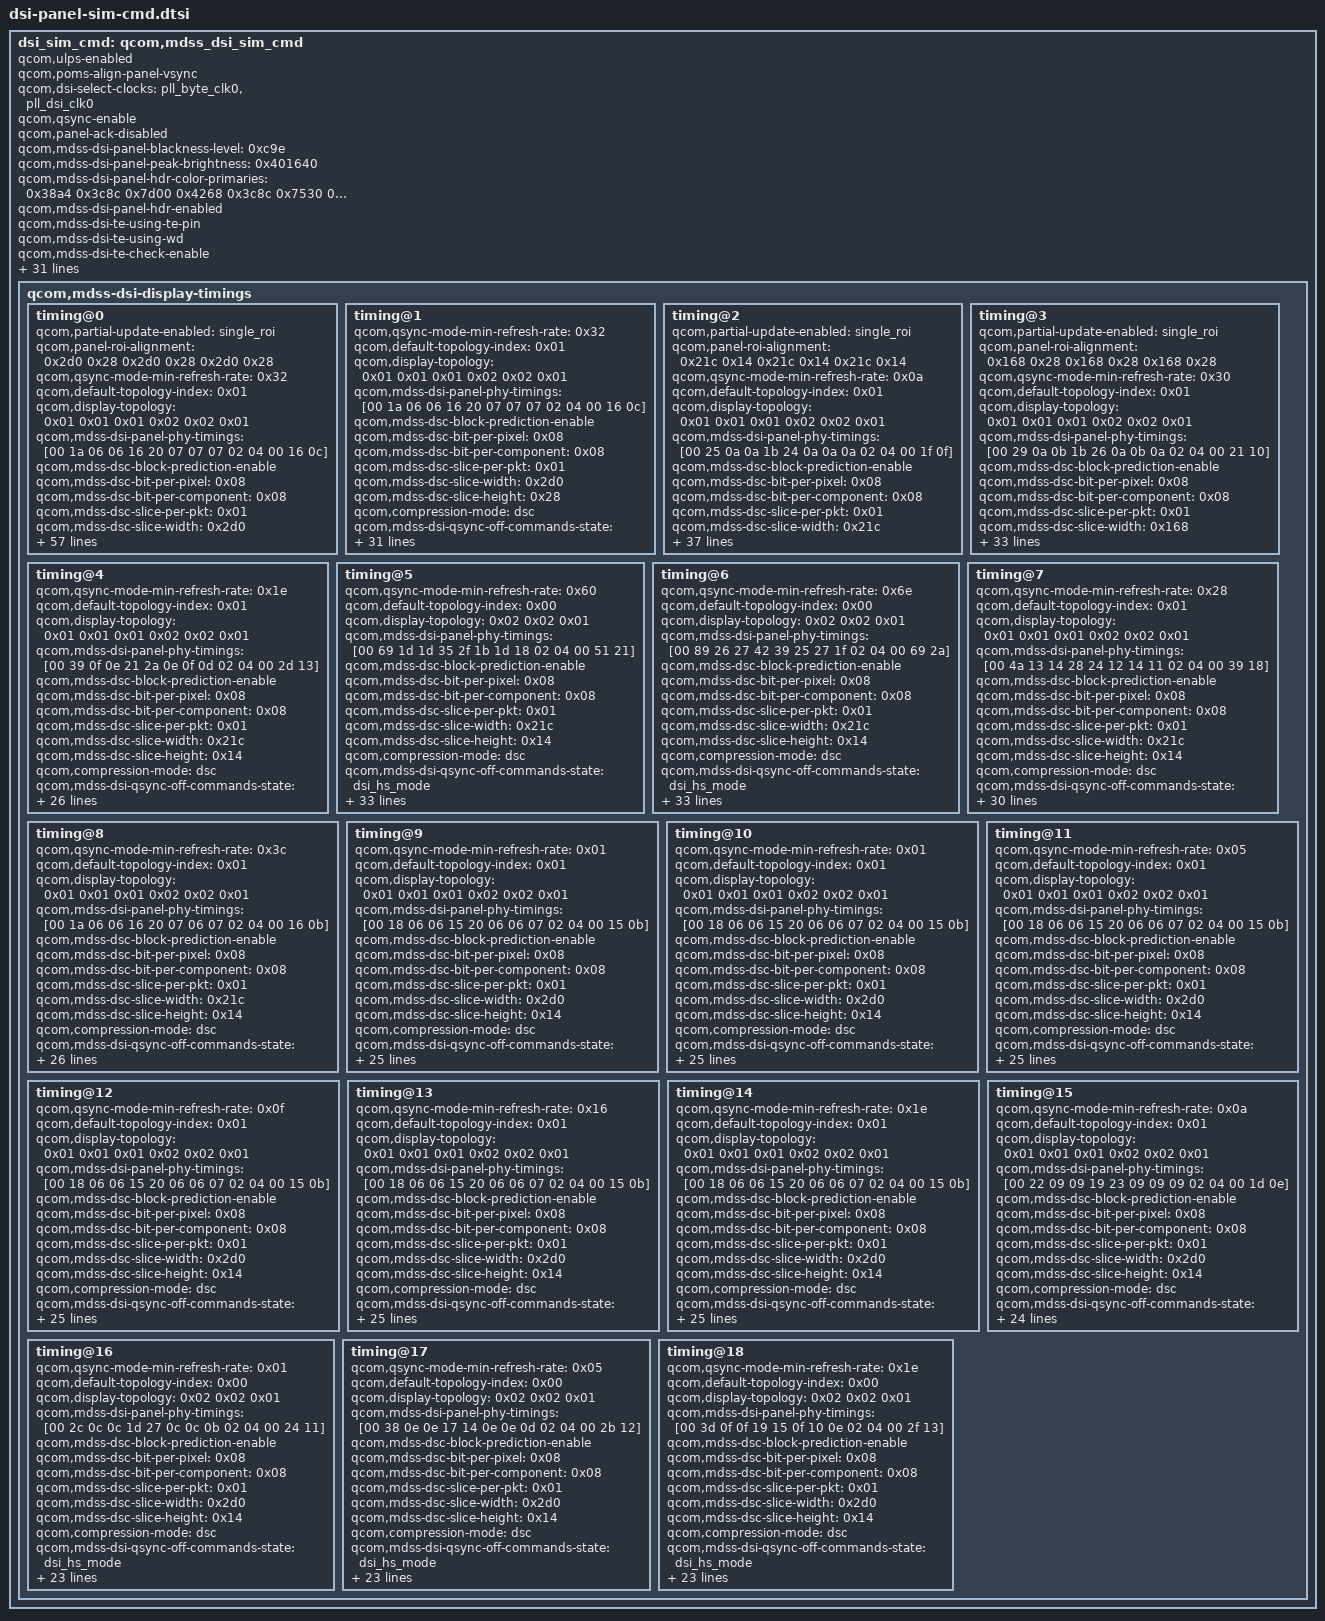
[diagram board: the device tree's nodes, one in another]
// SPDX-License-Identifier: BSD-3-Clause
/*
 * Copyright (c) 2023-2024 Qualcomm Innovation Center, Inc. All rights reserved.
 * Copyright (c) 2025 The LineageOS Project
 */

dsi_sim_cmd: qcom,mdss_dsi_sim_cmd {
	qcom,ulps-enabled;
	qcom,poms-align-panel-vsync;
	qcom,dsi-select-clocks = "pll_byte_clk0", "pll_dsi_clk0";
	qcom,qsync-enable;
	qcom,panel-ack-disabled;
	qcom,mdss-dsi-panel-blackness-level = <0xc9e>;
	qcom,mdss-dsi-panel-peak-brightness = <0x401640>;
	qcom,mdss-dsi-panel-hdr-color-primaries = <0x38a4 0x3c8c 0x7d00 0x4268 0x3c8c 0x7530 0x1f40 0xbb8>;
	qcom,mdss-dsi-panel-hdr-enabled;
	qcom,mdss-dsi-te-using-te-pin;
	qcom,mdss-dsi-te-using-wd;
	qcom,mdss-dsi-te-check-enable;
	qcom,mdss-dsi-te-dcs-command = <0x01>;
	qcom,mdss-dsi-wr-mem-continue = <0x3c>;
	qcom,mdss-dsi-wr-mem-start = <0x2c>;
	qcom,mdss-dsi-te-pin-select = <0x01>;
	qcom,mdss-dsi-mdp-trigger = "none";
	qcom,mdss-dsi-dma-trigger = "trigger_sw";
	qcom,mdss-dsi-bl-max-level = <0xfff>;
	qcom,mdss-dsi-t-clk-pre = <0x27>;
	qcom,mdss-dsi-t-clk-post = <0x03>;
	qcom,mdss-dsi-reset-sequence = <0x01 0x0a 0x00 0x0a 0x01 0x0a>;
	qcom,mdss-dsi-lane-3-state;
	qcom,mdss-dsi-lane-2-state;
	qcom,mdss-dsi-lane-1-state;
	qcom,mdss-dsi-lane-0-state;
	qcom,mdss-dsi-bllp-power-mode;
	qcom,mdss-dsi-bllp-eof-power-mode;
	qcom,mdss-dsi-traffic-mode = "non_burst_sync_event";
	qcom,mdss-dsi-panel-mode-switch;
	qcom,mdss-dsi-border-color = <0x00>;
	qcom,mdss-dsi-underflow-color = <0xff>;
	qcom,mdss-dsi-color-order = "rgb_swap_rgb";
	qcom,mdss-dsi-bpp = <0x18>;
	qcom,mdss-dsi-stream = <0x00>;
	qcom,mdss-dsi-virtual-channel-id = <0x00>;
	qcom,dsi-phy-num = <0x00>;
	qcom,dsi-ctrl-num = <0x00>;
	qcom,mdss-dsi-panel-type = "dsi_cmd_mode";
	qcom,mdss-dsi-panel-name = "Simulator cmd mode dsi panel";

	qcom,mdss-dsi-display-timings {

		timing@0 {
			qcom,partial-update-enabled = "single_roi";
			qcom,panel-roi-alignment = <0x2d0 0x28 0x2d0 0x28 0x2d0 0x28>;
			qcom,qsync-mode-min-refresh-rate = <0x32>;
			qcom,default-topology-index = <0x01>;
			qcom,display-topology = <0x01 0x01 0x01 0x02 0x02 0x01>;
			qcom,mdss-dsi-panel-phy-timings = [00 1a 06 06 16 20 07 07 07 02 04 00 16 0c];
			qcom,mdss-dsc-block-prediction-enable;
			qcom,mdss-dsc-bit-per-pixel = <0x08>;
			qcom,mdss-dsc-bit-per-component = <0x08>;
			qcom,mdss-dsc-slice-per-pkt = <0x01>;
			qcom,mdss-dsc-slice-width = <0x2d0>;
			qcom,mdss-dsc-slice-height = <0x28>;
			qcom,compression-mode = "dsc";
			qcom,mdss-dsi-qsync-off-commands-state = "dsi_hs_mode";
			qcom,mdss-dsi-qsync-off-commands = [15 01 00 00 00 00 02 51 00];
			qcom,mdss-dsi-qsync-on-commands-state = "dsi_hs_mode";
			qcom,mdss-dsi-qsync-on-commands = [15 01 00 00 00 00 02 51 00];
			qcom,cmd-mode-switch-out-commands-state = "dsi_lp_mode";
			qcom,cmd-mode-switch-out-commands = <0x39010000 0x3b0 0xa5000701 0x00 0x2010039 0x1000000 0x6b200 0x5d010249>;
			qcom,cmd-mode-switch-in-commands-state = "dsi_lp_mode";
			qcom,cmd-mode-switch-in-commands = [39 01 00 00 00 00 03 b0 a5 00 07 01 00 00 00 00 02 01 00 39 01 00 00 00 00 06 b2 00 5d 04 80 49 15 01 00 00 00 00 02 3d 11 15 01 00 00 00 00 02 36 00 15 01 00 00 00 00 02 55 0b];
			qcom,video-mode-switch-in-commands-state = "dsi_lp_mode";
			qcom,video-mode-switch-in-commands = [39 01 00 00 00 00 03 b0 a5 00 07 01 00 00 00 00 02 01 00 39 01 00 00 00 00 06 b2 00 5d 04 80 49 15 01 00 00 00 00 02 3d 10 15 01 00 00 00 00 02 36 00 15 01 00 00 00 00 02 55 0c];
			qcom,video-mode-switch-out-commands-state = "dsi_lp_mode";
			qcom,video-mode-switch-out-commands = <0x39010000 0x3b0 0xa5000701 0x00 0x2010039 0x1000000 0x6b200 0x5d048049>;
			qcom,mdss-dsi-off-command-state = "dsi_hs_mode";
			qcom,mdss-dsi-off-command = [05 01 00 00 32 00 02 28 00 05 01 00 00 78 00 02 10 00];
			qcom,mdss-dsi-on-command-state = "dsi_lp_mode";
			qcom,vid-on-commands = <0x29010000 0x2b0 0x3050100 0xa0001 0x150100 0xa0002 0x3a773901 0xa00 0x52a0000 0x4ff3901 0xa00 0x52b0000 0x59f1501 0xa00 0x2350039 0x100000a 0x34400 0x150100 0xa0002 0x51ff1501 0xa00 0x2532415 0x100000a 0x25500 0x5010000 0xf0000100>;
			qcom,cmd-on-commands = <0x29010000 0x2b0 0x3050100 0xa0001 0x150100 0xa0002 0x3a773901 0xa00 0x52a0000 0x4ff3901 0xa00 0x52b0000 0x59f1501 0xa00 0x2350039 0x100000a 0x34400 0x150100 0xa0002 0x51ff1501 0xa00 0x2532415 0x100000a 0x25500 0x5010000 0x78000111 0x5010000 0x10000129>;
			qcom,mdss-dsi-panel-timings = <0x210909 0x24230808 0x8030400>;
			qcom,dsi-wd-ltj-time-sec = <0xe10>;
			qcom,dsi-wd-ltj-max-jitter = <0x04 0x01>;
			qcom,mdss-dsi-panel-jitter = <0x02 0x01>;
			qcom,dsi-wd-jitter-enable;
			qcom,mdss-dsi-panel-framerate = <0x3c>;
			qcom,mdss-dsi-v-bottom-border = <0x00>;
			qcom,mdss-dsi-video-mode;
			qcom,mdss-dsi-cmd-mode;
			qcom,mdss-dsi-v-top-border = <0x00>;
			qcom,mdss-dsi-h-right-border = <0x00>;
			qcom,mdss-dsi-h-left-border = <0x00>;
			qcom,mdss-dsi-v-pulse-width = <0x28>;
			qcom,mdss-dsi-v-front-porch = <0x64>;
			qcom,mdss-dsi-v-back-porch = <0x64>;
			qcom,mdss-dsi-h-sync-skew = <0x00>;
			qcom,mdss-dsi-h-pulse-width = <0x28>;
			qcom,mdss-dsi-h-back-porch = <0x64>;
			qcom,mdss-dsi-h-front-porch = <0x78>;
			qcom,mdss-dsi-panel-height = <0xa00>;
			qcom,mdss-dsi-panel-width = <0x5a0>;
			cell-index = <0x00>;
		};

		timing@1 {
			qcom,qsync-mode-min-refresh-rate = <0x32>;
			qcom,default-topology-index = <0x01>;
			qcom,display-topology = <0x01 0x01 0x01 0x02 0x02 0x01>;
			qcom,mdss-dsi-panel-phy-timings = [00 1a 06 06 16 20 07 07 07 02 04 00 16 0c];
			qcom,mdss-dsc-block-prediction-enable;
			qcom,mdss-dsc-bit-per-pixel = <0x08>;
			qcom,mdss-dsc-bit-per-component = <0x08>;
			qcom,mdss-dsc-slice-per-pkt = <0x01>;
			qcom,mdss-dsc-slice-width = <0x2d0>;
			qcom,mdss-dsc-slice-height = <0x28>;
			qcom,compression-mode = "dsc";
			qcom,mdss-dsi-qsync-off-commands-state = "dsi_hs_mode";
			qcom,mdss-dsi-qsync-off-commands = [15 01 00 00 00 00 02 51 00];
			qcom,mdss-dsi-qsync-on-commands-state = "dsi_hs_mode";
			qcom,mdss-dsi-qsync-on-commands = [15 01 00 00 00 00 02 51 00];
			qcom,mdss-dsi-off-command-state = "dsi_hs_mode";
			qcom,mdss-dsi-off-command = [05 01 00 00 32 00 02 28 00 05 01 00 00 78 00 02 10 00];
			qcom,mdss-dsi-on-command-state = "dsi_lp_mode";
			qcom,mdss-dsi-on-command = <0x29010000 0x2b0 0x3050100 0xa0001 0x150100 0xa0002 0x3a773901 0xa00 0x52a0000 0x4ff3901 0xa00 0x52b0000 0x59f1501 0xa00 0x2350039 0x100000a 0x34400 0x150100 0xa0002 0x51ff1501 0xa00 0x2532415 0x100000a 0x25500 0x5010000 0xf0000100>;
			qcom,mdss-dsi-panel-timings = <0x210909 0x24230808 0x8030400>;
			qcom,mdss-dsi-video-mode;
			qcom,mdss-dsi-panel-framerate = <0x3c>;
			qcom,mdss-dsi-v-bottom-border = <0x00>;
			qcom,mdss-dsi-v-top-border = <0x00>;
			qcom,mdss-dsi-h-right-border = <0x00>;
			qcom,mdss-dsi-h-left-border = <0x00>;
			qcom,mdss-dsi-v-pulse-width = <0x28>;
			qcom,mdss-dsi-v-front-porch = <0x6e>;
			qcom,mdss-dsi-v-back-porch = <0x5a>;
			qcom,mdss-dsi-h-sync-skew = <0x00>;
			qcom,mdss-dsi-h-pulse-width = <0x28>;
			qcom,mdss-dsi-h-back-porch = <0x6e>;
			qcom,mdss-dsi-h-front-porch = <0x6e>;
			qcom,mdss-dsi-panel-height = <0xa00>;
			qcom,mdss-dsi-panel-width = <0x5a0>;
			cell-index = <0x01>;
		};

		timing@2 {
			qcom,partial-update-enabled = "single_roi";
			qcom,panel-roi-alignment = <0x21c 0x14 0x21c 0x14 0x21c 0x14>;
			qcom,qsync-mode-min-refresh-rate = <0x0a>;
			qcom,default-topology-index = <0x01>;
			qcom,display-topology = <0x01 0x01 0x01 0x02 0x02 0x01>;
			qcom,mdss-dsi-panel-phy-timings = [00 25 0a 0a 1b 24 0a 0a 0a 02 04 00 1f 0f];
			qcom,mdss-dsc-block-prediction-enable;
			qcom,mdss-dsc-bit-per-pixel = <0x08>;
			qcom,mdss-dsc-bit-per-component = <0x08>;
			qcom,mdss-dsc-slice-per-pkt = <0x01>;
			qcom,mdss-dsc-slice-width = <0x21c>;
			qcom,mdss-dsc-slice-height = <0x14>;
			qcom,compression-mode = "dsc";
			qcom,mdss-dsi-qsync-off-commands-state = "dsi_hs_mode";
			qcom,mdss-dsi-qsync-off-commands = [15 01 00 00 00 00 02 51 00];
			qcom,mdss-dsi-qsync-on-commands-state = "dsi_hs_mode";
			qcom,mdss-dsi-qsync-on-commands = [15 01 00 00 00 00 02 51 00];
			qcom,mdss-dsi-off-command-state = "dsi_hs_mode";
			qcom,mdss-dsi-off-command = [05 01 00 00 32 00 02 28 00 05 01 00 00 78 00 02 10 00];
			qcom,mdss-dsi-on-command-state = "dsi_lp_mode";
			qcom,mdss-dsi-on-command = <0x29010000 0x2b0 0x3050100 0xa0001 0x150100 0xa0002 0x3a773901 0xa00 0x52a0000 0x4ff3901 0xa00 0x52b0000 0x59f1501 0xa00 0x2350039 0x100000a 0x34400 0x150100 0xa0002 0x51ff1501 0xa00 0x2532415 0x100000a 0x25500 0x5010000 0xf0000100>;
			qcom,mdss-dsi-panel-timings = <0x210909 0x24230808 0x8030400>;
			qcom,dsi-wd-ltj-time-sec = <0xe10>;
			qcom,dsi-wd-ltj-max-jitter = <0x04 0x01>;
			qcom,mdss-dsi-panel-jitter = <0x02 0x01>;
			qcom,dsi-wd-jitter-enable;
			qcom,mdss-dsi-panel-framerate = <0x3c>;
			qcom,mdss-dsi-v-bottom-border = <0x00>;
			qcom,mdss-dsi-v-top-border = <0x00>;
			qcom,mdss-dsi-h-right-border = <0x00>;
			qcom,mdss-dsi-h-left-border = <0x00>;
			qcom,mdss-dsi-v-pulse-width = <0x28>;
			qcom,mdss-dsi-v-front-porch = <0x64>;
			qcom,mdss-dsi-v-back-porch = <0x64>;
			qcom,mdss-dsi-h-sync-skew = <0x00>;
			qcom,mdss-dsi-h-pulse-width = <0x28>;
			qcom,mdss-dsi-h-back-porch = <0x1cc>;
			qcom,mdss-dsi-h-front-porch = <0x78>;
			qcom,mdss-dsi-panel-height = <0x924>;
			qcom,mdss-dsi-panel-width = <0x438>;
			cell-index = <0x02>;
		};

		timing@3 {
			qcom,partial-update-enabled = "single_roi";
			qcom,panel-roi-alignment = <0x168 0x28 0x168 0x28 0x168 0x28>;
			qcom,qsync-mode-min-refresh-rate = <0x30>;
			qcom,default-topology-index = <0x01>;
			qcom,display-topology = <0x01 0x01 0x01 0x02 0x02 0x01>;
			qcom,mdss-dsi-panel-phy-timings = [00 29 0a 0b 1b 26 0a 0b 0a 02 04 00 21 10];
			qcom,mdss-dsc-block-prediction-enable;
			qcom,mdss-dsc-bit-per-pixel = <0x08>;
			qcom,mdss-dsc-bit-per-component = <0x08>;
			qcom,mdss-dsc-slice-per-pkt = <0x01>;
			qcom,mdss-dsc-slice-width = <0x168>;
			qcom,mdss-dsc-slice-height = <0x28>;
			qcom,compression-mode = "dsc";
			qcom,mdss-dsi-qsync-off-commands-state = "dsi_hs_mode";
			qcom,mdss-dsi-qsync-off-commands = [15 01 00 00 00 00 02 51 00];
			qcom,mdss-dsi-qsync-on-commands-state = "dsi_hs_mode";
			qcom,mdss-dsi-qsync-on-commands = [15 01 00 00 00 00 02 51 00];
			qcom,mdss-dsi-off-command-state = "dsi_hs_mode";
			qcom,mdss-dsi-off-command = [05 01 00 00 32 00 02 28 00 05 01 00 00 78 00 02 10 00];
			qcom,mdss-dsi-on-command-state = "dsi_lp_mode";
			qcom,mdss-dsi-on-command = <0x29010000 0x2b0 0x3050100 0xa0001 0x150100 0xa0002 0x3a773901 0xa00 0x52a0000 0x4ff3901 0xa00 0x52b0000 0x59f1501 0xa00 0x2350039 0x100000a 0x34400 0x150100 0xa0002 0x51ff1501 0xa00 0x2532415 0x100000a 0x25500 0x5010000 0xf0000100>;
			qcom,mdss-dsi-panel-timings = <0x210909 0x24230808 0x8030400>;
			qcom,mdss-dsi-panel-framerate = <0x3c>;
			qcom,mdss-dsi-v-bottom-border = <0x00>;
			qcom,mdss-dsi-v-top-border = <0x00>;
			qcom,mdss-dsi-h-right-border = <0x00>;
			qcom,mdss-dsi-h-left-border = <0x00>;
			qcom,mdss-dsi-v-pulse-width = <0x28>;
			qcom,mdss-dsi-v-front-porch = <0x64>;
			qcom,mdss-dsi-v-back-porch = <0x64>;
			qcom,mdss-dsi-h-sync-skew = <0x00>;
			qcom,mdss-dsi-h-pulse-width = <0x28>;
			qcom,mdss-dsi-h-back-porch = <0x348>;
			qcom,mdss-dsi-h-front-porch = <0x64>;
			qcom,mdss-dsi-panel-height = <0x500>;
			qcom,mdss-dsi-panel-width = <0x2d0>;
			cell-index = <0x03>;
		};

		timing@4 {
			qcom,qsync-mode-min-refresh-rate = <0x1e>;
			qcom,default-topology-index = <0x01>;
			qcom,display-topology = <0x01 0x01 0x01 0x02 0x02 0x01>;
			qcom,mdss-dsi-panel-phy-timings = [00 39 0f 0e 21 2a 0e 0f 0d 02 04 00 2d 13];
			qcom,mdss-dsc-block-prediction-enable;
			qcom,mdss-dsc-bit-per-pixel = <0x08>;
			qcom,mdss-dsc-bit-per-component = <0x08>;
			qcom,mdss-dsc-slice-per-pkt = <0x01>;
			qcom,mdss-dsc-slice-width = <0x21c>;
			qcom,mdss-dsc-slice-height = <0x14>;
			qcom,compression-mode = "dsc";
			qcom,mdss-dsi-qsync-off-commands-state = "dsi_hs_mode";
			qcom,mdss-dsi-qsync-off-commands = [15 01 00 00 00 00 02 51 00];
			qcom,mdss-dsi-qsync-on-commands-state = "dsi_hs_mode";
			qcom,mdss-dsi-qsync-on-commands = [15 01 00 00 00 00 02 51 00];
			qcom,mdss-dsi-off-command-state = "dsi_hs_mode";
			qcom,mdss-dsi-off-command = [05 01 00 00 32 00 02 28 00 05 01 00 00 78 00 02 10 00];
			qcom,mdss-dsi-on-command-state = "dsi_lp_mode";
			qcom,mdss-dsi-on-command = <0x29010000 0x2b0 0x3050100 0xa0001 0x150100 0xa0002 0x3a773901 0xa00 0x52a0000 0x4ff3901 0xa00 0x52b0000 0x59f1501 0xa00 0x2350039 0x100000a 0x34400 0x150100 0xa0002 0x51ff1501 0xa00 0x2532415 0x100000a 0x25500 0x5010000 0x78000111 0x5010000 0x10000129>;
			qcom,mdss-dsi-panel-timings = <0x210909 0x24230808 0x8030400>;
			qcom,mdss-dsi-panel-framerate = <0x5a>;
			qcom,mdss-dsi-v-pulse-width = <0x28>;
			qcom,mdss-dsi-v-front-porch = <0x64>;
			qcom,mdss-dsi-v-back-porch = <0x64>;
			qcom,mdss-dsi-h-sync-skew = <0x00>;
			qcom,mdss-dsi-h-pulse-width = <0x28>;
			qcom,mdss-dsi-h-back-porch = <0x1cc>;
			qcom,mdss-dsi-h-front-porch = <0x78>;
			qcom,mdss-dsi-panel-height = <0x924>;
			qcom,mdss-dsi-panel-width = <0x438>;
			cell-index = <0x04>;
		};

		timing@5 {
			qcom,qsync-mode-min-refresh-rate = <0x60>;
			qcom,default-topology-index = <0x00>;
			qcom,display-topology = <0x02 0x02 0x01>;
			qcom,mdss-dsi-panel-phy-timings = [00 69 1d 1d 35 2f 1b 1d 18 02 04 00 51 21];
			qcom,mdss-dsc-block-prediction-enable;
			qcom,mdss-dsc-bit-per-pixel = <0x08>;
			qcom,mdss-dsc-bit-per-component = <0x08>;
			qcom,mdss-dsc-slice-per-pkt = <0x01>;
			qcom,mdss-dsc-slice-width = <0x21c>;
			qcom,mdss-dsc-slice-height = <0x14>;
			qcom,compression-mode = "dsc";
			qcom,mdss-dsi-qsync-off-commands-state = "dsi_hs_mode";
			qcom,mdss-dsi-qsync-off-commands = [15 01 00 00 00 00 02 51 00];
			qcom,mdss-dsi-qsync-on-commands-state = "dsi_hs_mode";
			qcom,mdss-dsi-qsync-on-commands = [15 01 00 00 00 00 02 51 00];
			qcom,mdss-dsi-off-command-state = "dsi_hs_mode";
			qcom,mdss-dsi-off-command = [05 01 00 00 32 00 02 28 00 05 01 00 00 78 00 02 10 00];
			qcom,mdss-dsi-on-command-state = "dsi_lp_mode";
			qcom,mdss-dsi-on-command = <0x29010000 0x2b0 0x3050100 0xa0001 0x150100 0xa0002 0x3a773901 0xa00 0x52a0000 0x4ff3901 0xa00 0x52b0000 0x59f1501 0xa00 0x2350039 0x100000a 0x34400 0x150100 0xa0002 0x51ff1501 0xa00 0x2532415 0x100000a 0x25500>;
			qcom,disable-rsc-solver;
			qcom,dsi-wd-ltj-time-sec = <0xe10>;
			qcom,dsi-wd-ltj-max-jitter = <0x04 0x01>;
			qcom,mdss-dsi-panel-jitter = <0x02 0x01>;
			qcom,dsi-wd-jitter-enable;
			qcom,mdss-dsi-panel-framerate = <0xb4>;
			qcom,mdss-dsi-v-bottom-border = <0x00>;
			qcom,mdss-dsi-v-top-border = <0x00>;
			qcom,mdss-dsi-h-right-border = <0x00>;
			qcom,mdss-dsi-h-left-border = <0x00>;
			qcom,mdss-dsi-h-sync-pulse = <0x00>;
			qcom,mdss-dsi-v-pulse-width = <0x28>;
			qcom,mdss-dsi-v-front-porch = <0x64>;
			qcom,mdss-dsi-v-back-porch = <0x64>;
			qcom,mdss-dsi-h-sync-skew = <0x00>;
			qcom,mdss-dsi-h-pulse-width = <0x28>;
			qcom,mdss-dsi-h-back-porch = <0x1cc>;
			qcom,mdss-dsi-h-front-porch = <0x78>;
			qcom,mdss-dsi-panel-height = <0x924>;
			qcom,mdss-dsi-panel-width = <0x438>;
			cell-index = <0x05>;
		};

		timing@6 {
			qcom,qsync-mode-min-refresh-rate = <0x6e>;
			qcom,default-topology-index = <0x00>;
			qcom,display-topology = <0x02 0x02 0x01>;
			qcom,mdss-dsi-panel-phy-timings = [00 89 26 27 42 39 25 27 1f 02 04 00 69 2a];
			qcom,mdss-dsc-block-prediction-enable;
			qcom,mdss-dsc-bit-per-pixel = <0x08>;
			qcom,mdss-dsc-bit-per-component = <0x08>;
			qcom,mdss-dsc-slice-per-pkt = <0x01>;
			qcom,mdss-dsc-slice-width = <0x21c>;
			qcom,mdss-dsc-slice-height = <0x14>;
			qcom,compression-mode = "dsc";
			qcom,mdss-dsi-qsync-off-commands-state = "dsi_hs_mode";
			qcom,mdss-dsi-qsync-off-commands = [15 01 00 00 00 00 02 51 00];
			qcom,mdss-dsi-qsync-on-commands-state = "dsi_hs_mode";
			qcom,mdss-dsi-qsync-on-commands = [15 01 00 00 00 00 02 51 00];
			qcom,mdss-dsi-off-command-state = "dsi_hs_mode";
			qcom,mdss-dsi-off-command = [05 01 00 00 32 00 02 28 00 05 01 00 00 78 00 02 10 00];
			qcom,mdss-dsi-on-command-state = "dsi_lp_mode";
			qcom,mdss-dsi-on-command = <0x29010000 0x2b0 0x3050100 0xa0001 0x150100 0xa0002 0x3a773901 0xa00 0x52a0000 0x4ff3901 0xa00 0x52b0000 0x59f1501 0xa00 0x2350039 0x100000a 0x34400 0x150100 0xa0002 0x51ff1501 0xa00 0x2532415 0x100000a 0x25500 0x5010000 0xf0000100>;
			qcom,disable-rsc-solver;
			qcom,dsi-wd-ltj-time-sec = <0xe10>;
			qcom,dsi-wd-ltj-max-jitter = <0x04 0x01>;
			qcom,mdss-dsi-panel-jitter = <0x02 0x01>;
			qcom,dsi-wd-jitter-enable;
			qcom,mdss-dsi-panel-framerate = <0xf0>;
			qcom,mdss-dsi-v-bottom-border = <0x00>;
			qcom,mdss-dsi-v-top-border = <0x00>;
			qcom,mdss-dsi-h-right-border = <0x00>;
			qcom,mdss-dsi-h-left-border = <0x00>;
			qcom,mdss-dsi-h-sync-pulse = <0x00>;
			qcom,mdss-dsi-v-pulse-width = <0x28>;
			qcom,mdss-dsi-v-front-porch = <0x64>;
			qcom,mdss-dsi-v-back-porch = <0x64>;
			qcom,mdss-dsi-h-sync-skew = <0x00>;
			qcom,mdss-dsi-h-pulse-width = <0x28>;
			qcom,mdss-dsi-h-back-porch = <0x1cc>;
			qcom,mdss-dsi-h-front-porch = <0x78>;
			qcom,mdss-dsi-panel-height = <0x924>;
			qcom,mdss-dsi-panel-width = <0x438>;
			cell-index = <0x06>;
		};

		timing@7 {
			qcom,qsync-mode-min-refresh-rate = <0x28>;
			qcom,default-topology-index = <0x01>;
			qcom,display-topology = <0x01 0x01 0x01 0x02 0x02 0x01>;
			qcom,mdss-dsi-panel-phy-timings = [00 4a 13 14 28 24 12 14 11 02 04 00 39 18];
			qcom,mdss-dsc-block-prediction-enable;
			qcom,mdss-dsc-bit-per-pixel = <0x08>;
			qcom,mdss-dsc-bit-per-component = <0x08>;
			qcom,mdss-dsc-slice-per-pkt = <0x01>;
			qcom,mdss-dsc-slice-width = <0x21c>;
			qcom,mdss-dsc-slice-height = <0x14>;
			qcom,compression-mode = "dsc";
			qcom,mdss-dsi-qsync-off-commands-state = "dsi_hs_mode";
			qcom,mdss-dsi-qsync-off-commands = [15 01 00 00 00 00 02 51 00];
			qcom,mdss-dsi-qsync-on-commands-state = "dsi_hs_mode";
			qcom,mdss-dsi-qsync-on-commands = [15 01 00 00 00 00 02 51 00];
			qcom,mdss-dsi-off-command-state = "dsi_hs_mode";
			qcom,mdss-dsi-off-command = [05 01 00 00 32 00 02 28 00 05 01 00 00 78 00 02 10 00];
			qcom,mdss-dsi-on-command-state = "dsi_lp_mode";
			qcom,mdss-dsi-on-command = <0x29010000 0x2b0 0x3050100 0xa0001 0x150100 0xa0002 0x3a773901 0xa00 0x52a0000 0x4ff3901 0xa00 0x52b0000 0x59f1501 0xa00 0x2350039 0x100000a 0x34400 0x150100 0xa0002 0x51ff1501 0xa00 0x2532415 0x100000a 0x25500 0x5010000 0x78000111 0x5010000 0x10000129>;
			qcom,mdss-dsi-panel-timings = <0x210909 0x24230808 0x8030400>;
			qcom,mdss-dsi-panel-framerate = <0x78>;
			qcom,mdss-dsi-v-bottom-border = <0x00>;
			qcom,mdss-dsi-v-top-border = <0x00>;
			qcom,mdss-dsi-h-right-border = <0x00>;
			qcom,mdss-dsi-h-left-border = <0x00>;
			qcom,mdss-dsi-v-pulse-width = <0x28>;
			qcom,mdss-dsi-v-front-porch = <0x64>;
			qcom,mdss-dsi-v-back-porch = <0x64>;
			qcom,mdss-dsi-h-sync-skew = <0x00>;
			qcom,mdss-dsi-h-pulse-width = <0x28>;
			qcom,mdss-dsi-h-back-porch = <0x1cc>;
			qcom,mdss-dsi-h-front-porch = <0x78>;
			qcom,mdss-dsi-panel-height = <0x924>;
			qcom,mdss-dsi-panel-width = <0x438>;
			cell-index = <0x07>;
		};

		timing@8 {
			qcom,qsync-mode-min-refresh-rate = <0x3c>;
			qcom,default-topology-index = <0x01>;
			qcom,display-topology = <0x01 0x01 0x01 0x02 0x02 0x01>;
			qcom,mdss-dsi-panel-phy-timings = [00 1a 06 06 16 20 07 06 07 02 04 00 16 0b];
			qcom,mdss-dsc-block-prediction-enable;
			qcom,mdss-dsc-bit-per-pixel = <0x08>;
			qcom,mdss-dsc-bit-per-component = <0x08>;
			qcom,mdss-dsc-slice-per-pkt = <0x01>;
			qcom,mdss-dsc-slice-width = <0x21c>;
			qcom,mdss-dsc-slice-height = <0x14>;
			qcom,compression-mode = "dsc";
			qcom,mdss-dsi-qsync-off-commands-state = "dsi_hs_mode";
			qcom,mdss-dsi-qsync-off-commands = [15 01 00 00 00 00 02 51 00];
			qcom,mdss-dsi-qsync-on-commands-state = "dsi_hs_mode";
			qcom,mdss-dsi-qsync-on-commands = [15 01 00 00 00 00 02 51 00];
			qcom,mdss-dsi-off-command-state = "dsi_hs_mode";
			qcom,mdss-dsi-off-command = [05 01 00 00 32 00 02 28 00 05 01 00 00 78 00 02 10 00];
			qcom,mdss-dsi-on-command-state = "dsi_lp_mode";
			qcom,mdss-dsi-on-command = <0x29010000 0x2b0 0x3050100 0xa0001 0x150100 0xa0002 0x3a773901 0xa00 0x52a0000 0x4ff3901 0xa00 0x52b0000 0x59f1501 0xa00 0x2350039 0x100000a 0x34400 0x150100 0xa0002 0x51ff1501 0xa00 0x2532415 0x100000a 0x25500 0x5010000 0x78000111 0x5010000 0x10000129>;
			qcom,mdss-dsi-panel-timings = <0x210909 0x24230808 0x8030400>;
			qcom,mdss-dsi-panel-framerate = <0x90>;
			qcom,mdss-dsi-v-pulse-width = <0x28>;
			qcom,mdss-dsi-v-front-porch = <0x64>;
			qcom,mdss-dsi-v-back-porch = <0x64>;
			qcom,mdss-dsi-h-sync-skew = <0x00>;
			qcom,mdss-dsi-h-pulse-width = <0x28>;
			qcom,mdss-dsi-h-back-porch = <0x1cc>;
			qcom,mdss-dsi-h-front-porch = <0x78>;
			qcom,mdss-dsi-panel-height = <0x924>;
			qcom,mdss-dsi-panel-width = <0x438>;
			cell-index = <0x08>;
		};

		timing@9 {
			qcom,qsync-mode-min-refresh-rate = <0x01>;
			qcom,default-topology-index = <0x01>;
			qcom,display-topology = <0x01 0x01 0x01 0x02 0x02 0x01>;
			qcom,mdss-dsi-panel-phy-timings = [00 18 06 06 15 20 06 06 07 02 04 00 15 0b];
			qcom,mdss-dsc-block-prediction-enable;
			qcom,mdss-dsc-bit-per-pixel = <0x08>;
			qcom,mdss-dsc-bit-per-component = <0x08>;
			qcom,mdss-dsc-slice-per-pkt = <0x01>;
			qcom,mdss-dsc-slice-width = <0x2d0>;
			qcom,mdss-dsc-slice-height = <0x14>;
			qcom,compression-mode = "dsc";
			qcom,mdss-dsi-qsync-off-commands-state = "dsi_hs_mode";
			qcom,mdss-dsi-qsync-off-commands = [15 01 00 00 00 00 02 51 00];
			qcom,mdss-dsi-qsync-on-commands-state = "dsi_hs_mode";
			qcom,mdss-dsi-qsync-on-commands = [15 01 00 00 00 00 02 51 00];
			qcom,mdss-dsi-off-command-state = "dsi_hs_mode";
			qcom,mdss-dsi-off-command = [05 01 00 00 32 00 02 28 00 05 01 00 00 78 00 02 10 00];
			qcom,mdss-dsi-on-command-state = "dsi_lp_mode";
			qcom,mdss-dsi-on-command = <0x29010000 0x2b0 0x3050100 0xa0001 0x150100 0xa0002 0x3a773901 0xa00 0x52a0000 0x4ff3901 0xa00 0x52b0000 0x59f1501 0xa00 0x2350039 0x100000a 0x34400 0x150100 0xa0002 0x51ff1501 0xa00 0x2532415 0x100000a 0x25500 0x5010000 0x78000111 0x5010000 0x10000129>;
			qcom,mdss-mdp-transfer-time-us = <15866>;
			qcom,mdss-dsi-panel-framerate = <0x01>;
			qcom,mdss-dsi-v-pulse-width = <0x02>;
			qcom,mdss-dsi-v-front-porch = <0x14>;
			qcom,mdss-dsi-v-back-porch = <0x14>;
			qcom,mdss-dsi-h-sync-skew = <0x00>;
			qcom,mdss-dsi-h-pulse-width = <0x04>;
			qcom,mdss-dsi-h-back-porch = <0x0c>;
			qcom,mdss-dsi-h-front-porch = <0x14>;
			qcom,mdss-dsi-panel-height = <0xe4c>;
			qcom,mdss-dsi-panel-width = <0x5a0>;
			cell-index = <0x09>;
		};

		timing@10 {
			qcom,qsync-mode-min-refresh-rate = <0x01>;
			qcom,default-topology-index = <0x01>;
			qcom,display-topology = <0x01 0x01 0x01 0x02 0x02 0x01>;
			qcom,mdss-dsi-panel-phy-timings = [00 18 06 06 15 20 06 06 07 02 04 00 15 0b];
			qcom,mdss-dsc-block-prediction-enable;
			qcom,mdss-dsc-bit-per-pixel = <0x08>;
			qcom,mdss-dsc-bit-per-component = <0x08>;
			qcom,mdss-dsc-slice-per-pkt = <0x01>;
			qcom,mdss-dsc-slice-width = <0x2d0>;
			qcom,mdss-dsc-slice-height = <0x14>;
			qcom,compression-mode = "dsc";
			qcom,mdss-dsi-qsync-off-commands-state = "dsi_hs_mode";
			qcom,mdss-dsi-qsync-off-commands = [15 01 00 00 00 00 02 51 00];
			qcom,mdss-dsi-qsync-on-commands-state = "dsi_hs_mode";
			qcom,mdss-dsi-qsync-on-commands = [15 01 00 00 00 00 02 51 00];
			qcom,mdss-dsi-off-command-state = "dsi_hs_mode";
			qcom,mdss-dsi-off-command = [05 01 00 00 32 00 02 28 00 05 01 00 00 78 00 02 10 00];
			qcom,mdss-dsi-on-command-state = "dsi_lp_mode";
			qcom,mdss-dsi-on-command = <0x29010000 0x2b0 0x3050100 0xa0001 0x150100 0xa0002 0x3a773901 0xa00 0x52a0000 0x4ff3901 0xa00 0x52b0000 0x59f1501 0xa00 0x2350039 0x100000a 0x34400 0x150100 0xa0002 0x51ff1501 0xa00 0x2532415 0x100000a 0x25500 0x5010000 0x78000111 0x5010000 0x10000129>;
			qcom,mdss-mdp-transfer-time-us = <15866>;
			qcom,mdss-dsi-panel-framerate = <0x05>;
			qcom,mdss-dsi-v-pulse-width = <0x02>;
			qcom,mdss-dsi-v-front-porch = <0x14>;
			qcom,mdss-dsi-v-back-porch = <0x14>;
			qcom,mdss-dsi-h-sync-skew = <0x00>;
			qcom,mdss-dsi-h-pulse-width = <0x04>;
			qcom,mdss-dsi-h-back-porch = <0x0c>;
			qcom,mdss-dsi-h-front-porch = <0x14>;
			qcom,mdss-dsi-panel-height = <0xe4c>;
			qcom,mdss-dsi-panel-width = <0x5a0>;
			cell-index = <0x0a>;
		};

		timing@11 {
			qcom,qsync-mode-min-refresh-rate = <0x05>;
			qcom,default-topology-index = <0x01>;
			qcom,display-topology = <0x01 0x01 0x01 0x02 0x02 0x01>;
			qcom,mdss-dsi-panel-phy-timings = [00 18 06 06 15 20 06 06 07 02 04 00 15 0b];
			qcom,mdss-dsc-block-prediction-enable;
			qcom,mdss-dsc-bit-per-pixel = <0x08>;
			qcom,mdss-dsc-bit-per-component = <0x08>;
			qcom,mdss-dsc-slice-per-pkt = <0x01>;
			qcom,mdss-dsc-slice-width = <0x2d0>;
			qcom,mdss-dsc-slice-height = <0x14>;
			qcom,compression-mode = "dsc";
			qcom,mdss-dsi-qsync-off-commands-state = "dsi_hs_mode";
			qcom,mdss-dsi-qsync-off-commands = [15 01 00 00 00 00 02 51 00];
			qcom,mdss-dsi-qsync-on-commands-state = "dsi_hs_mode";
			qcom,mdss-dsi-qsync-on-commands = [15 01 00 00 00 00 02 51 00];
			qcom,mdss-dsi-off-command-state = "dsi_hs_mode";
			qcom,mdss-dsi-off-command = [05 01 00 00 32 00 02 28 00 05 01 00 00 78 00 02 10 00];
			qcom,mdss-dsi-on-command-state = "dsi_lp_mode";
			qcom,mdss-dsi-on-command = <0x29010000 0x2b0 0x3050100 0xa0001 0x150100 0xa0002 0x3a773901 0xa00 0x52a0000 0x4ff3901 0xa00 0x52b0000 0x59f1501 0xa00 0x2350039 0x100000a 0x34400 0x150100 0xa0002 0x51ff1501 0xa00 0x2532415 0x100000a 0x25500 0x5010000 0x78000111 0x5010000 0x10000129>;
			qcom,mdss-mdp-transfer-time-us = <15866>;
			qcom,mdss-dsi-panel-framerate = <0x0a>;
			qcom,mdss-dsi-v-pulse-width = <0x02>;
			qcom,mdss-dsi-v-front-porch = <0x14>;
			qcom,mdss-dsi-v-back-porch = <0x14>;
			qcom,mdss-dsi-h-sync-skew = <0x00>;
			qcom,mdss-dsi-h-pulse-width = <0x04>;
			qcom,mdss-dsi-h-back-porch = <0x0c>;
			qcom,mdss-dsi-h-front-porch = <0x14>;
			qcom,mdss-dsi-panel-height = <0xe4c>;
			qcom,mdss-dsi-panel-width = <0x5a0>;
			cell-index = <0x0b>;
		};

		timing@12 {
			qcom,qsync-mode-min-refresh-rate = <0x0f>;
			qcom,default-topology-index = <0x01>;
			qcom,display-topology = <0x01 0x01 0x01 0x02 0x02 0x01>;
			qcom,mdss-dsi-panel-phy-timings = [00 18 06 06 15 20 06 06 07 02 04 00 15 0b];
			qcom,mdss-dsc-block-prediction-enable;
			qcom,mdss-dsc-bit-per-pixel = <0x08>;
			qcom,mdss-dsc-bit-per-component = <0x08>;
			qcom,mdss-dsc-slice-per-pkt = <0x01>;
			qcom,mdss-dsc-slice-width = <0x2d0>;
			qcom,mdss-dsc-slice-height = <0x14>;
			qcom,compression-mode = "dsc";
			qcom,mdss-dsi-qsync-off-commands-state = "dsi_hs_mode";
			qcom,mdss-dsi-qsync-off-commands = [15 01 00 00 00 00 02 51 00];
			qcom,mdss-dsi-qsync-on-commands-state = "dsi_hs_mode";
			qcom,mdss-dsi-qsync-on-commands = [15 01 00 00 00 00 02 51 00];
			qcom,mdss-dsi-off-command-state = "dsi_hs_mode";
			qcom,mdss-dsi-off-command = [05 01 00 00 32 00 02 28 00 05 01 00 00 78 00 02 10 00];
			qcom,mdss-dsi-on-command-state = "dsi_lp_mode";
			qcom,mdss-dsi-on-command = <0x29010000 0x2b0 0x3050100 0xa0001 0x150100 0xa0002 0x3a773901 0xa00 0x52a0000 0x4ff3901 0xa00 0x52b0000 0x59f1501 0xa00 0x2350039 0x100000a 0x34400 0x150100 0xa0002 0x51ff1501 0xa00 0x2532415 0x100000a 0x25500 0x5010000 0x78000111 0x5010000 0x10000129>;
			qcom,mdss-mdp-transfer-time-us = <15866>;
			qcom,mdss-dsi-panel-framerate = <0x18>;
			qcom,mdss-dsi-v-pulse-width = <0x02>;
			qcom,mdss-dsi-v-front-porch = <0x14>;
			qcom,mdss-dsi-v-back-porch = <0x14>;
			qcom,mdss-dsi-h-sync-skew = <0x00>;
			qcom,mdss-dsi-h-pulse-width = <0x04>;
			qcom,mdss-dsi-h-back-porch = <0x0c>;
			qcom,mdss-dsi-h-front-porch = <0x14>;
			qcom,mdss-dsi-panel-height = <0xe4c>;
			qcom,mdss-dsi-panel-width = <0x5a0>;
			cell-index = <0x0c>;
		};

		timing@13 {
			qcom,qsync-mode-min-refresh-rate = <0x16>;
			qcom,default-topology-index = <0x01>;
			qcom,display-topology = <0x01 0x01 0x01 0x02 0x02 0x01>;
			qcom,mdss-dsi-panel-phy-timings = [00 18 06 06 15 20 06 06 07 02 04 00 15 0b];
			qcom,mdss-dsc-block-prediction-enable;
			qcom,mdss-dsc-bit-per-pixel = <0x08>;
			qcom,mdss-dsc-bit-per-component = <0x08>;
			qcom,mdss-dsc-slice-per-pkt = <0x01>;
			qcom,mdss-dsc-slice-width = <0x2d0>;
			qcom,mdss-dsc-slice-height = <0x14>;
			qcom,compression-mode = "dsc";
			qcom,mdss-dsi-qsync-off-commands-state = "dsi_hs_mode";
			qcom,mdss-dsi-qsync-off-commands = [15 01 00 00 00 00 02 51 00];
			qcom,mdss-dsi-qsync-on-commands-state = "dsi_hs_mode";
			qcom,mdss-dsi-qsync-on-commands = [15 01 00 00 00 00 02 51 00];
			qcom,mdss-dsi-off-command-state = "dsi_hs_mode";
			qcom,mdss-dsi-off-command = [05 01 00 00 32 00 02 28 00 05 01 00 00 78 00 02 10 00];
			qcom,mdss-dsi-on-command-state = "dsi_lp_mode";
			qcom,mdss-dsi-on-command = <0x29010000 0x2b0 0x3050100 0xa0001 0x150100 0xa0002 0x3a773901 0xa00 0x52a0000 0x4ff3901 0xa00 0x52b0000 0x59f1501 0xa00 0x2350039 0x100000a 0x34400 0x150100 0xa0002 0x51ff1501 0xa00 0x2532415 0x100000a 0x25500 0x5010000 0x78000111 0x5010000 0x10000129>;
			qcom,mdss-mdp-transfer-time-us = <15866>;
			qcom,mdss-dsi-panel-framerate = <0x1e>;
			qcom,mdss-dsi-v-pulse-width = <0x02>;
			qcom,mdss-dsi-v-front-porch = <0x14>;
			qcom,mdss-dsi-v-back-porch = <0x14>;
			qcom,mdss-dsi-h-sync-skew = <0x00>;
			qcom,mdss-dsi-h-pulse-width = <0x04>;
			qcom,mdss-dsi-h-back-porch = <0x0c>;
			qcom,mdss-dsi-h-front-porch = <0x14>;
			qcom,mdss-dsi-panel-height = <0xe4c>;
			qcom,mdss-dsi-panel-width = <0x5a0>;
			cell-index = <0x0d>;
		};

		timing@14 {
			qcom,qsync-mode-min-refresh-rate = <0x1e>;
			qcom,default-topology-index = <0x01>;
			qcom,display-topology = <0x01 0x01 0x01 0x02 0x02 0x01>;
			qcom,mdss-dsi-panel-phy-timings = [00 18 06 06 15 20 06 06 07 02 04 00 15 0b];
			qcom,mdss-dsc-block-prediction-enable;
			qcom,mdss-dsc-bit-per-pixel = <0x08>;
			qcom,mdss-dsc-bit-per-component = <0x08>;
			qcom,mdss-dsc-slice-per-pkt = <0x01>;
			qcom,mdss-dsc-slice-width = <0x2d0>;
			qcom,mdss-dsc-slice-height = <0x14>;
			qcom,compression-mode = "dsc";
			qcom,mdss-dsi-qsync-off-commands-state = "dsi_hs_mode";
			qcom,mdss-dsi-qsync-off-commands = [15 01 00 00 00 00 02 51 00];
			qcom,mdss-dsi-qsync-on-commands-state = "dsi_hs_mode";
			qcom,mdss-dsi-qsync-on-commands = [15 01 00 00 00 00 02 51 00];
			qcom,mdss-dsi-off-command-state = "dsi_hs_mode";
			qcom,mdss-dsi-off-command = [05 01 00 00 32 00 02 28 00 05 01 00 00 78 00 02 10 00];
			qcom,mdss-dsi-on-command-state = "dsi_lp_mode";
			qcom,mdss-dsi-on-command = <0x29010000 0x2b0 0x3050100 0xa0001 0x150100 0xa0002 0x3a773901 0xa00 0x52a0000 0x4ff3901 0xa00 0x52b0000 0x59f1501 0xa00 0x2350039 0x100000a 0x34400 0x150100 0xa0002 0x51ff1501 0xa00 0x2532415 0x100000a 0x25500 0x5010000 0x78000111 0x5010000 0x10000129>;
			qcom,mdss-mdp-transfer-time-us = <15866>;
			qcom,mdss-dsi-panel-framerate = <0x3c>;
			qcom,mdss-dsi-v-pulse-width = <0x02>;
			qcom,mdss-dsi-v-front-porch = <0x14>;
			qcom,mdss-dsi-v-back-porch = <0x14>;
			qcom,mdss-dsi-h-sync-skew = <0x00>;
			qcom,mdss-dsi-h-pulse-width = <0x04>;
			qcom,mdss-dsi-h-back-porch = <0x0c>;
			qcom,mdss-dsi-h-front-porch = <0x14>;
			qcom,mdss-dsi-panel-height = <0xe4c>;
			qcom,mdss-dsi-panel-width = <0x5a0>;
			cell-index = <0x0e>;
		};

		timing@15 {
			qcom,qsync-mode-min-refresh-rate = <0x0a>;
			qcom,default-topology-index = <0x01>;
			qcom,display-topology = <0x01 0x01 0x01 0x02 0x02 0x01>;
			qcom,mdss-dsi-panel-phy-timings = [00 22 09 09 19 23 09 09 09 02 04 00 1d 0e];
			qcom,mdss-dsc-block-prediction-enable;
			qcom,mdss-dsc-bit-per-pixel = <0x08>;
			qcom,mdss-dsc-bit-per-component = <0x08>;
			qcom,mdss-dsc-slice-per-pkt = <0x01>;
			qcom,mdss-dsc-slice-width = <0x2d0>;
			qcom,mdss-dsc-slice-height = <0x14>;
			qcom,compression-mode = "dsc";
			qcom,mdss-dsi-qsync-off-commands-state = "dsi_hs_mode";
			qcom,mdss-dsi-qsync-off-commands = [15 01 00 00 00 00 02 51 00];
			qcom,mdss-dsi-qsync-on-commands-state = "dsi_hs_mode";
			qcom,mdss-dsi-qsync-on-commands = [15 01 00 00 00 00 02 51 00];
			qcom,mdss-dsi-off-command-state = "dsi_hs_mode";
			qcom,mdss-dsi-off-command = [05 01 00 00 32 00 02 28 00 05 01 00 00 78 00 02 10 00];
			qcom,mdss-dsi-on-command-state = "dsi_lp_mode";
			qcom,mdss-dsi-on-command = <0x29010000 0x2b0 0x3050100 0xa0001 0x150100 0xa0002 0x3a773901 0xa00 0x52a0000 0x4ff3901 0xa00 0x52b0000 0x59f1501 0xa00 0x2350039 0x100000a 0x34400 0x150100 0xa0002 0x51ff1501 0xa00 0x2532415 0x100000a 0x25500 0x5010000 0x78000111 0x5010000 0x10000129>;
			qcom,mdss-dsi-panel-framerate = <0x5a>;
			qcom,mdss-dsi-v-pulse-width = <0x02>;
			qcom,mdss-dsi-v-front-porch = <0x14>;
			qcom,mdss-dsi-v-back-porch = <0x14>;
			qcom,mdss-dsi-h-sync-skew = <0x00>;
			qcom,mdss-dsi-h-pulse-width = <0x04>;
			qcom,mdss-dsi-h-back-porch = <0x0c>;
			qcom,mdss-dsi-h-front-porch = <0x14>;
			qcom,mdss-dsi-panel-height = <0xe4c>;
			qcom,mdss-dsi-panel-width = <0x5a0>;
			cell-index = <0x0f>;
		};

		timing@16 {
			qcom,qsync-mode-min-refresh-rate = <0x01>;
			qcom,default-topology-index = <0x00>;
			qcom,display-topology = <0x02 0x02 0x01>;
			qcom,mdss-dsi-panel-phy-timings = [00 2c 0c 0c 1d 27 0c 0c 0b 02 04 00 24 11];
			qcom,mdss-dsc-block-prediction-enable;
			qcom,mdss-dsc-bit-per-pixel = <0x08>;
			qcom,mdss-dsc-bit-per-component = <0x08>;
			qcom,mdss-dsc-slice-per-pkt = <0x01>;
			qcom,mdss-dsc-slice-width = <0x2d0>;
			qcom,mdss-dsc-slice-height = <0x14>;
			qcom,compression-mode = "dsc";
			qcom,mdss-dsi-qsync-off-commands-state = "dsi_hs_mode";
			qcom,mdss-dsi-qsync-off-commands = [15 01 00 00 00 00 02 51 00];
			qcom,mdss-dsi-qsync-on-commands-state = "dsi_hs_mode";
			qcom,mdss-dsi-qsync-on-commands = [15 01 00 00 00 00 02 51 00];
			qcom,mdss-dsi-off-command-state = "dsi_hs_mode";
			qcom,mdss-dsi-off-command = [05 01 00 00 32 00 02 28 00 05 01 00 00 78 00 02 10 00];
			qcom,mdss-dsi-on-command-state = "dsi_lp_mode";
			qcom,mdss-dsi-on-command = <0x29010000 0x2b0 0x3050100 0xa0001 0x150100 0xa0002 0x3a773901 0xa00 0x52a0000 0x4ff3901 0xa00 0x52b0000 0x59f1501 0xa00 0x2350039 0x100000a 0x34400 0x150100 0xa0002 0x51ff1501 0xa00 0x2532415 0x100000a 0x25500 0x5010000 0x78000111 0x5010000 0x10000129>;
			qcom,mdss-dsi-panel-framerate = <0x78>;
			qcom,mdss-dsi-v-pulse-width = <0x02>;
			qcom,mdss-dsi-v-front-porch = <0x14>;
			qcom,mdss-dsi-v-back-porch = <0x14>;
			qcom,mdss-dsi-h-sync-skew = <0x00>;
			qcom,mdss-dsi-h-pulse-width = <0x04>;
			qcom,mdss-dsi-h-back-porch = <0x0c>;
			qcom,mdss-dsi-h-front-porch = <0x14>;
			qcom,mdss-dsi-panel-height = <0xe4c>;
			qcom,mdss-dsi-panel-width = <0x5a0>;
			cell-index = <0x10>;
		};

		timing@17 {
			qcom,qsync-mode-min-refresh-rate = <0x05>;
			qcom,default-topology-index = <0x00>;
			qcom,display-topology = <0x02 0x02 0x01>;
			qcom,mdss-dsi-panel-phy-timings = [00 38 0e 0e 17 14 0e 0e 0d 02 04 00 2b 12];
			qcom,mdss-dsc-block-prediction-enable;
			qcom,mdss-dsc-bit-per-pixel = <0x08>;
			qcom,mdss-dsc-bit-per-component = <0x08>;
			qcom,mdss-dsc-slice-per-pkt = <0x01>;
			qcom,mdss-dsc-slice-width = <0x2d0>;
			qcom,mdss-dsc-slice-height = <0x14>;
			qcom,compression-mode = "dsc";
			qcom,mdss-dsi-qsync-off-commands-state = "dsi_hs_mode";
			qcom,mdss-dsi-qsync-off-commands = [15 01 00 00 00 00 02 51 00];
			qcom,mdss-dsi-qsync-on-commands-state = "dsi_hs_mode";
			qcom,mdss-dsi-qsync-on-commands = [15 01 00 00 00 00 02 51 00];
			qcom,mdss-dsi-off-command-state = "dsi_hs_mode";
			qcom,mdss-dsi-off-command = [05 01 00 00 32 00 02 28 00 05 01 00 00 78 00 02 10 00];
			qcom,mdss-dsi-on-command-state = "dsi_lp_mode";
			qcom,mdss-dsi-on-command = <0x29010000 0x2b0 0x3050100 0xa0001 0x150100 0xa0002 0x3a773901 0xa00 0x52a0000 0x4ff3901 0xa00 0x52b0000 0x59f1501 0xa00 0x2350039 0x100000a 0x34400 0x150100 0xa0002 0x51ff1501 0xa00 0x2532415 0x100000a 0x25500 0x5010000 0x78000111 0x5010000 0x10000129>;
			qcom,mdss-dsi-panel-framerate = <0x90>;
			qcom,mdss-dsi-v-pulse-width = <0x02>;
			qcom,mdss-dsi-v-front-porch = <0x14>;
			qcom,mdss-dsi-v-back-porch = <0x14>;
			qcom,mdss-dsi-h-sync-skew = <0x00>;
			qcom,mdss-dsi-h-pulse-width = <0x04>;
			qcom,mdss-dsi-h-back-porch = <0x0c>;
			qcom,mdss-dsi-h-front-porch = <0x14>;
			qcom,mdss-dsi-panel-height = <0xe4c>;
			qcom,mdss-dsi-panel-width = <0x5a0>;
			cell-index = <0x11>;
		};

		timing@18 {
			qcom,qsync-mode-min-refresh-rate = <0x1e>;
			qcom,default-topology-index = <0x00>;
			qcom,display-topology = <0x02 0x02 0x01>;
			qcom,mdss-dsi-panel-phy-timings = [00 3d 0f 0f 19 15 0f 10 0e 02 04 00 2f 13];
			qcom,mdss-dsc-block-prediction-enable;
			qcom,mdss-dsc-bit-per-pixel = <0x08>;
			qcom,mdss-dsc-bit-per-component = <0x08>;
			qcom,mdss-dsc-slice-per-pkt = <0x01>;
			qcom,mdss-dsc-slice-width = <0x2d0>;
			qcom,mdss-dsc-slice-height = <0x14>;
			qcom,compression-mode = "dsc";
			qcom,mdss-dsi-qsync-off-commands-state = "dsi_hs_mode";
			qcom,mdss-dsi-qsync-off-commands = [15 01 00 00 00 00 02 51 00];
			qcom,mdss-dsi-qsync-on-commands-state = "dsi_hs_mode";
			qcom,mdss-dsi-qsync-on-commands = [15 01 00 00 00 00 02 51 00];
			qcom,mdss-dsi-off-command-state = "dsi_hs_mode";
			qcom,mdss-dsi-off-command = [05 01 00 00 32 00 02 28 00 05 01 00 00 78 00 02 10 00];
			qcom,mdss-dsi-on-command-state = "dsi_lp_mode";
			qcom,mdss-dsi-on-command = <0x29010000 0x2b0 0x3050100 0xa0001 0x150100 0xa0002 0x3a773901 0xa00 0x52a0000 0x4ff3901 0xa00 0x52b0000 0x59f1501 0xa00 0x2350039 0x100000a 0x34400 0x150100 0xa0002 0x51ff1501 0xa00 0x2532415 0x100000a 0x25500 0x5010000 0x78000111 0x5010000 0x10000129>;
			qcom,mdss-dsi-panel-framerate = <0xb4>;
			qcom,mdss-dsi-v-pulse-width = <0x02>;
			qcom,mdss-dsi-v-front-porch = <0x14>;
			qcom,mdss-dsi-v-back-porch = <0x14>;
			qcom,mdss-dsi-h-sync-skew = <0x00>;
			qcom,mdss-dsi-h-pulse-width = <0x04>;
			qcom,mdss-dsi-h-back-porch = <0x0c>;
			qcom,mdss-dsi-h-front-porch = <0x14>;
			qcom,mdss-dsi-panel-height = <0xc80>;
			qcom,mdss-dsi-panel-width = <0x5a0>;
			cell-index = <0x12>;
		};
	};
};
